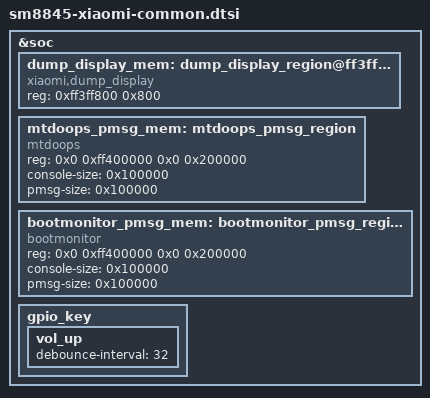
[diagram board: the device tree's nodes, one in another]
#include "alor-mtp.dtsi"

&soc {
	dump_display_mem: dump_display_region@ff3ff800 {
		compatible = "xiaomi,dump_display";
		reg = <0xff3ff800 0x800>;
	};

	mtdoops_pmsg_mem: mtdoops_pmsg_region {
		compatible = "mtdoops";
		reg = <0x0 0xff400000 0x0 0x200000>;
		console-size = <0x100000>;
		pmsg-size = <0x100000>;
	};

	bootmonitor_pmsg_mem: bootmonitor_pmsg_region {
		compatible = "bootmonitor";
		reg = <0x0 0xff400000 0x0 0x200000>;
		console-size = <0x100000>;
		pmsg-size = <0x100000>;
	};

	gpio_key {
		vol_up {
			debounce-interval = <32>;
		};
	};
};
